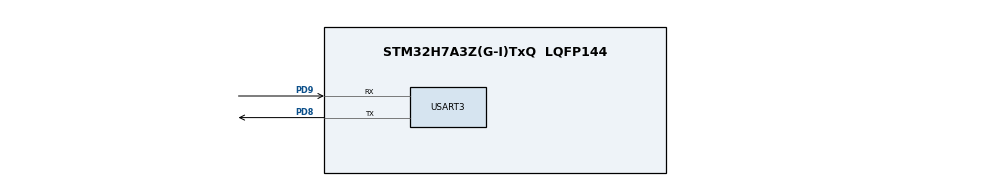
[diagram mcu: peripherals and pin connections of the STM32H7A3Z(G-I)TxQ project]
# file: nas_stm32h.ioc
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Mcu.Family=STM32H7
RCC.DFSDMCLockSelection=RCC_DFSDM1CLKSOURCE_D2PCLK1
PH0-OSC_IN.Signal=RCC_OSC_IN
RCC.CortexFreq_Value=100000000
STMicroelectronics.X-CUBE-AI.8.0.1.useInputAllocation=true
STMicroelectronics.X-CUBE-AI.8.0.1.ModelNameList=network
RCC.PLLFRACN=4096
STMicroelectronics.X-CUBE-AI.8.0.1.MaximumNumberOfInputLayer=1
STMicroelectronics.X-CUBE-AI.8.0.1.customLayerConfigEnabled=false
RCC.PLL2FRACN=0
STMicroelectronics.X-CUBE-AI.8.0.1.MaximumSizeOfOutputLayer=1
PD9.Mode=Asynchronous
RCC.SYSCLKSource=RCC_SYSCLKSOURCE_PLLCLK
ProjectManager.StackSize=0x800
RCC.SPI123CLockSelection=RCC_SPI123CLKSOURCE_PLL
USART3.VirtualMode-Asynchronous=VM_ASYNC
RCC.LPUART1CLockSelection=RCC_LPUART1CLKSOURCE_D3PCLK1
STMicroelectronics.X-CUBE-AI.8.0.1.copyWeightToRam=false
RCC.I2C4CLockSelection=RCC_I2C4CLKSOURCE_D3PCLK1
RCC.RCC_MCO2Source=RCC_MCO2SOURCE_SYSCLK
RCC.ADCCLockSelection=RCC_ADCCLKSOURCE_PLL2
RCC.HCLKFreq_Value=100000000
RCC.SAI2BCLockSelection=RCC_SAI2BCLKSOURCE_PLL
STMicroelectronics.X-CUBE-AI.8.0.1.XAaCUBEAaAICcArtificialOoIntelligenceJjCore=true
STMicroelectronics.X-CUBE-AI.8.0.1.ModelRamOccupation-0abbc9bb6c1aad92f61149516d385fa65a44edc42774e28c7ebe2bdf62b45bf3=78772
PD8.Signal=USART3_TX
STMicroelectronics.X-CUBE-AI.8.0.1.ModelActualCompression-0abbc9bb6c1aad92f61149516d385fa65a44edc42774e28c7ebe2bdf62b45bf3=0.0
PH0-OSC_IN.Mode=HSE-External-Clock-Source
RCC.HSE_VALUE=8000000
RCC.I2C123CLockSelection=RCC_I2C123CLKSOURCE_D2PCLK1
STMicroelectronics.X-CUBE-AI.8.0.1.ModelHashList=0abbc9bb6c1aad92f61149516d385fa65a44edc42774e28c7ebe2bdf62b45bf3
RCC.DIVM1=4
RCC.RCC_MCO1Source=RCC_MCO1SOURCE_HSI
STMicroelectronics.X-CUBE-AI.8.0.1.MaximumNumberOfOutputLayer=1
STMicroelectronics.X-CUBE-AI.8.0.1.ReadyForCodeGeneration=true
RCC.LPTIM2CLockSelection=RCC_LPTIM2CLKSOURCE_D3PCLK1
RCC.SAI1CLockSelection=RCC_SAI1CLKSOURCE_PLL
STMicroelectronics.X-CUBE-AI.8.0.1.ModelKind-0abbc9bb6c1aad92f61149516d385fa65a44edc42774e28c7ebe2bdf62b45bf3=TFLITE
RCC.LPTIM345CLockSelection=RCC_LPTIM3CLKSOURCE_D3PCLK1
RCC.SPDIFCLockSelection=RCC_SPDIFRXCLKSOURCE_PLL
RCC.CKPERSourceSelection=RCC_CLKPSOURCE_HSI
STMicroelectronics.X-CUBE-AI.8.0.1.ActivationSizes=AI_NETWORK_DATA_ACTIVATION_1_SIZE
RCC.APB3Freq_Value=50000000
Mcu.Package=LQFP144
STMicroelectronics.X-CUBE-AI.8.0.1.useOutputAllocation=true
RCC.PLL3FRACN=0
STMicroelectronics.X-CUBE-AI.8.0.1.LatestDirectoryUsed-0abbc9bb6c1aad92f61149516d385fa65a44edc42774e28c7ebe2bdf62b45bf3=F\:\\verified_model
STMicroelectronics.X-CUBE-AI.8.0.1.ActivationNames=pool0
STMicroelectronics.X-CUBE-AI.8.0.1.ModelFlashOccupation-0abbc9bb6c1aad92f61149516d385fa65a44edc42774e28c7ebe2bdf62b45bf3=397440
RCC.APB4Freq_Value=50000000
RCC.FDCANCLockSelection=RCC_FDCANCLKSOURCE_PLL
STMicroelectronics.X-CUBE-AI.8.0.1.ActivationBuffers=pool0
STMicroelectronics.X-CUBE-AI.8.0.1.ModelType-0abbc9bb6c1aad92f61149516d385fa65a44edc42774e28c7ebe2bdf62b45bf3=STM32Cube.AI runtime
RCC.SRDPPRE=RCC_APB4_DIV2
RCC.HSI48_VALUE=48000000
CORTEX_M7.CPU_ICache=Enabled
STMicroelectronics.X-CUBE-AI.8.0.1.HeapSize=0x800
RCC.EXTERNAL_CLOCK_VALUE=12288000
STMicroelectronics.X-CUBE-AI.8.0.1.ModelCompression-0abbc9bb6c1aad92f61149516d385fa65a44edc42774e28c7ebe2bdf62b45bf3=None
PD9.Signal=USART3_RX
RCC.Cortex_DivARG=SystemCoreClock/1000
RCC.CDPPRE1=RCC_APB1_DIV2
RCC.CDPPRE2=RCC_APB2_DIV2
ProjectManager.TargetToolchain=STM32CubeIDE
RCC.SPI6CLockSelection=RCC_SPI6CLKSOURCE_D3PCLK1
STMicroelectronics.X-CUBE-AI.8.0.1.StackSize=0x800
RCC.CECCLockSelection=RCC_CECCLKSOURCE_LSI
RCC.DIVN1=12
RCC.LPTIM1CLockSelection=RCC_LPTIM1CLKSOURCE_D2PCLK1
RCC.USBFreq_Value=100000000
RCC.SWPCLockSelection=RCC_SWPMI1CLKSOURCE_D2PCLK1
RCC.LSE_VALUE=32768
PD8.Mode=Asynchronous
RCC.USBCLockSelection=RCC_USBCLKSOURCE_PLL
STMicroelectronics.X-CUBE-AI.8.0.1.MaximumSizeOfInputLayer=1
board=custom
STMicroelectronics.X-CUBE-AI.8.0.1.ActivationBufferSizeList=78772
RCC.APB2Freq_Value=50000000
RCC.RNGCLockSelection=RCC_RNGCLKSOURCE_HSI48
RCC.FMCCLockSelection=RCC_FMCCLKSOURCE_D1HCLK
STMicroelectronics.X-CUBE-AI.8.0.1.ModelStructureFile-0abbc9bb6c1aad92f61149516d385fa65a44edc42774e28c7ebe2bdf62b45bf3=F\:\\verified_model\\nas_full_integer_quant.tflite
RCC.ADCFreq_Value=129000000
STMicroelectronics.X-CUBE-AI.8.0.1.ModelName-0abbc9bb6c1aad92f61149516d385fa65a44edc42774e28c7ebe2bdf62b45bf3=network
RCC.CSI_VALUE=4000000
RCC.CDPPRE=RCC_APB3_DIV2
Mcu.Name=STM32H7A3Z(G-I)TxQ
VP_STMicroelectronics.X-CUBE-AI_VS_ArtificialOoIntelligenceJjXAaCUBEAaAI_8.0.1.Mode=ArtificialOoIntelligenceJjXAaCUBEAaAI
STMicroelectronics.X-CUBE-AI.8.0.1.ModelMacc-0abbc9bb6c1aad92f61149516d385fa65a44edc42774e28c7ebe2bdf62b45bf3=36473034
RCC.SYSCLKFreq_VALUE=100000000
RCC.Spi45ClockSelection=RCC_SPI45CLKSOURCE_D2PCLK1
STMicroelectronics.X-CUBE-AI.8.0.1.WorkingBufferStartAddrList=0xFFFFFFFF
RCC.QSPICLockSelection=RCC_OSPICLKSOURCE_D1HCLK
ProjectManager.HeapSize=0x800
RCC.HSI_VALUE=64000000
NVIC.PriorityGroup=NVIC_PRIORITYGROUP_4
RCC.USART234578CLockSelection=RCC_USART234578CLKSOURCE_D2PCLK1
CORTEX_M7.CPU_DCache=Enabled
RCC.APB1Freq_Value=50000000
VP_CRC_VS_CRC.Mode=CRC_Activate
RCC.USART16CLockSelection=RCC_USART16910CLKSOURCE_D2PCLK2
STMicroelectronics.X-CUBE-AI.8.0.1.InternalRamActivationBufferMaxSize=AI_NETWORK_DATA_ACTIVATIONS_SIZE

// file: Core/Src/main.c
/* USER CODE BEGIN Header */
/**
  ******************************************************************************
  * @file           : main.c
  * @brief          : Main program body
  ******************************************************************************
  * @attention
  *
  * <h2><center>&copy; Copyright (c) 2025 STMicroelectronics.
  * All rights reserved.</center></h2>
  *
  * This software component is licensed by ST under BSD 3-Clause license,
  * the "License"; You may not use this file except in compliance with the
  * License. You may obtain a copy of the License at:
  *                        opensource.org/licenses/BSD-3-Clause
  *
  ******************************************************************************
  */
/* USER CODE END Header */
#include "main.h"

/* USER CODE BEGIN Includes */
/* USER CODE BEGIN Includes */
#include <stdio.h>
#include "network.h"
#include "network_data.h"
#include "ai_datatypes_defines.h"
#include "ai_platform.h"
#include <math.h>

/* USER CODE END Includes */

/* USER CODE END Includes */

CRC_HandleTypeDef hcrc;

UART_HandleTypeDef huart3;

void SystemClock_Config(void);
static void MX_GPIO_Init(void);
static void MX_CRC_Init(void);
static void MX_USART3_UART_Init(void);

/* USER CODE BEGIN 0 */
/* USER CODE BEGIN 0 */
/* Global handle to reference the instantiated C-model */
static ai_handle network = AI_HANDLE_NULL;

/* Global c-array to handle the activations buffer */
AI_ALIGNED(32)
static ai_u8 activations[AI_NETWORK_DATA_ACTIVATIONS_SIZE];

/* Array to store the data of the input tensor */
AI_ALIGNED(32)
static ai_float in_data[AI_NETWORK_IN_1_SIZE];
/* or static ai_u8 in_data[AI_NETWORK_IN_1_SIZE_BYTES]; */

/* c-array to store the data of the output tensor */
AI_ALIGNED(32)
static ai_float out_data[AI_NETWORK_OUT_1_SIZE];
/* static ai_u8 out_data[AI_NETWORK_OUT_1_SIZE_BYTES]; */

/* Array of pointer to manage the model's input/output tensors */
static ai_buffer *ai_input;
static ai_buffer *ai_output;

/* Define global variables */
char buf[50]; // Define printf
int buf_len = 0;
ai_error err;
//
int acquire_and_process_data(const void *in_data){

//	AI_ALIGNED(4) ai_i8 in_data[AI_SINE_MODEL_IN_1_SIZE_BYTES];
//	AI_ALIGNED(4) ai_i8 out_data[AI_SINE_MODEL_OUT_1_SIZE_BYTES];

	for (uint32_t i = 0; i < AI_NETWORK_IN_1_SIZE; i++)
	{
		((ai_float *)in_data)[i] = (ai_float)2.0f;
	}

	return 0;
}
int aiInit(void) {
//  ai_error err;

  /* Create and initialize the c-model */
  const ai_handle acts[] = { activations };
  err = ai_network_create_and_init(&network, acts, NULL);
  if (err.type != AI_ERROR_NONE) {
	  buf_len = sprintf(buf, "Error: could not create NN instance\r\n");
	  HAL_UART_Transmit(&huart3, (uint8_t *)buf, buf_len, 100);
	  while(1);
 };

  /* Reteive pointers to the model's input/output tensors */
  ai_input = ai_network_inputs_get(network, NULL);
  ai_output = ai_network_outputs_get(network, NULL);

  return 0;
}

int aiRun(const void *in_data, void *out_data) {
  ai_i32 n_batch;
//  ai_error err;

  /* 1 - Update IO handlers with the data payload */
  ai_input[0].data = AI_HANDLE_PTR(in_data);
  ai_output[0].data = AI_HANDLE_PTR(out_data);

  /* 2 - Perform the inference */
  n_batch = ai_network_run(network, &ai_input[0], &ai_output[0]);
  if (n_batch != 1) {
      err = ai_network_get_error(network);
	  buf_len = sprintf(buf, "Error: could not run inference \r\n");
	  HAL_UART_Transmit(&huart3, (uint8_t *)buf, buf_len, 100);

  };

  return 0;
}

int post_process(void *out_data){
	float y_val = ((float *)out_data)[0];
	buf_len = sprintf(buf,"Output: %f", y_val);
	HAL_UART_Transmit(&huart3, (uint8_t *)buf, buf_len, 100);

	return 0;
}

int softmax_process(void *out_data)
{
    float *logits = (float *)out_data;

    float max_val = logits[0];
    for (int i = 1; i < AI_NETWORK_OUT_1_SIZE; i++)
    {
        if (logits[i] > max_val)
        {
            max_val = logits[i];
        }
    }

    float sum_exp = 0.0f;
    for (int i = 0; i < AI_NETWORK_OUT_1_SIZE; i++)
    {
        logits[i] = expf(logits[i] - max_val);
        sum_exp += logits[i];
    }

    for (int i = 0; i < AI_NETWORK_OUT_1_SIZE; i++)
    {
        logits[i] /= sum_exp;
    }

//    buf_len = sprintf(buf, "Output[0] = %f\r\n", logits[0]);
//    HAL_UART_Transmit(&huart3, (uint8_t *)buf, buf_len, 100);

    return 0;
}

/* USER CODE END 0 */

/* USER CODE END 0 */

int main(void)
{
  /* USER CODE BEGIN 1 */
	/* USER CODE BEGIN 1 */

	__HAL_RCC_CRC_CLK_ENABLE();

	uint32_t timestamp;

	/* USER CODE END 1 */

  /* USER CODE END 1 */

  /* Enable I-Cache---------------------------------------------------------*/
  SCB_EnableICache();

  /* Enable D-Cache---------------------------------------------------------*/
  SCB_EnableDCache();

  /* MCU Configuration--------------------------------------------------------*/

  /* Reset of all peripherals, Initializes the Flash interface and the Systick. */
  HAL_Init();

  /* Configure the system clock */
  SystemClock_Config();

  /* Initialize all configured peripherals */
  MX_GPIO_Init();
  MX_CRC_Init();
  MX_USART3_UART_Init();
  /* USER CODE BEGIN 2 */
  /* USER CODE BEGIN 2 */

  HAL_UART_Init(&huart3);
  // Greetings
  buf_len = sprintf(buf, "\r\n\r\nSTM32 X-Cube-AI test\r\n");
  HAL_UART_Transmit(&huart3, (uint8_t *)buf, buf_len, 100);

  /* USER CODE END 2 */

  /* USER CODE END 2 */

  /* Infinite loop */
  while (1)
  {
	  /* 1 - Acquire, pre-process and fill the input buffers */
	  uint32_t start_time_init = HAL_GetTick(); // time start
	  for (int i = 0; i < 1000; i++)
	  {
		  aiInit();
		  acquire_and_process_data(in_data);
	  }
	  uint32_t end_time_init = HAL_GetTick(); // time end
	  uint32_t total_time_init = end_time_init - start_time_init;
	  float average_time_init = (float)total_time_init / 1000; // ms
	  char buf_init[32];
	  int buf_len_init = sprintf(buf_init, "Init Time: %.3f ms\r\n", average_time_init);
	  HAL_UART_Transmit(&huart3, (uint8_t *)buf_init, buf_len_init, HAL_MAX_DELAY);

	  /* 2 - Call inference engine */
	  uint32_t start_time_inf = HAL_GetTick(); // time start

	  for (int i = 0; i < 1; i++)
	  {
		  aiRun(in_data, out_data);
	  }

	  uint32_t end_time_inf = HAL_GetTick(); // time end
	  uint32_t total_time_inf = end_time_inf - start_time_inf;
	  float average_time_inf = (float)total_time_inf / 1; // ms
	  char buf_inf[32];
	  int buf_len_inf = sprintf(buf_inf, "CNN Time: %.3f ms\r\n", average_time_inf);
	  HAL_UART_Transmit(&huart3, (uint8_t *)buf_inf, buf_len_inf, HAL_MAX_DELAY);

	  /* 3 - Post-process the predictions */
//	  post_process(out_data);
	  uint32_t start_time_sm = HAL_GetTick(); // time start
	  for (int i = 0; i < 1000; i++)
	  {
	      softmax_process(out_data);
	  }
	  uint32_t end_time_sm = HAL_GetTick(); // time end
	  uint32_t total_time_sm = end_time_sm - start_time_sm;
	  float average_time_sm = (float)total_time_sm / 1000; // ms
	  char buf_sm[32];
	  int buf_len_sm = sprintf(buf_sm, "Softmax Time: %.3f ms\r\n", average_time_sm);
	  HAL_UART_Transmit(&huart3, (uint8_t *)buf_sm, buf_len_sm, HAL_MAX_DELAY);

	  /* USER CODE END WHILE */
	  HAL_Delay(500);

  }
}

void SystemClock_Config(void)
{
  RCC_OscInitTypeDef RCC_OscInitStruct = {0};
  RCC_ClkInitTypeDef RCC_ClkInitStruct = {0};

  /** Supply configuration update enable
  */
  HAL_PWREx_ConfigSupply(PWR_DIRECT_SMPS_SUPPLY);
  /** Configure the main internal regulator output voltage
  */
  __HAL_PWR_VOLTAGESCALING_CONFIG(PWR_REGULATOR_VOLTAGE_SCALE2);

  while(!__HAL_PWR_GET_FLAG(PWR_FLAG_VOSRDY)) {}
  /** Initializes the RCC Oscillators according to the specified parameters
  * in the RCC_OscInitTypeDef structure.
  */
  RCC_OscInitStruct.OscillatorType = RCC_OSCILLATORTYPE_HSI;
  RCC_OscInitStruct.HSIState = RCC_HSI_DIV1;
  RCC_OscInitStruct.HSICalibrationValue = RCC_HSICALIBRATION_DEFAULT;
  RCC_OscInitStruct.PLL.PLLState = RCC_PLL_ON;
  RCC_OscInitStruct.PLL.PLLSource = RCC_PLLSOURCE_HSI;
  RCC_OscInitStruct.PLL.PLLM = 4;
  RCC_OscInitStruct.PLL.PLLN = 12;
  RCC_OscInitStruct.PLL.PLLP = 2;
  RCC_OscInitStruct.PLL.PLLQ = 2;
  RCC_OscInitStruct.PLL.PLLR = 2;
  RCC_OscInitStruct.PLL.PLLRGE = RCC_PLL1VCIRANGE_3;
  RCC_OscInitStruct.PLL.PLLVCOSEL = RCC_PLL1VCOWIDE;
  RCC_OscInitStruct.PLL.PLLFRACN = 4096;
  if (HAL_RCC_OscConfig(&RCC_OscInitStruct) != HAL_OK)
  {
    Error_Handler();
  }
  /** Initializes the CPU, AHB and APB buses clocks
  */
  RCC_ClkInitStruct.ClockType = RCC_CLOCKTYPE_HCLK|RCC_CLOCKTYPE_SYSCLK
                              |RCC_CLOCKTYPE_PCLK1|RCC_CLOCKTYPE_PCLK2
                              |RCC_CLOCKTYPE_D3PCLK1|RCC_CLOCKTYPE_D1PCLK1;
  RCC_ClkInitStruct.SYSCLKSource = RCC_SYSCLKSOURCE_PLLCLK;
  RCC_ClkInitStruct.SYSCLKDivider = RCC_SYSCLK_DIV1;
  RCC_ClkInitStruct.AHBCLKDivider = RCC_HCLK_DIV1;
  RCC_ClkInitStruct.APB3CLKDivider = RCC_APB3_DIV2;
  RCC_ClkInitStruct.APB1CLKDivider = RCC_APB1_DIV2;
  RCC_ClkInitStruct.APB2CLKDivider = RCC_APB2_DIV2;
  RCC_ClkInitStruct.APB4CLKDivider = RCC_APB4_DIV2;

  if (HAL_RCC_ClockConfig(&RCC_ClkInitStruct, FLASH_LATENCY_2) != HAL_OK)
  {
    Error_Handler();
  }
}

static void MX_CRC_Init(void)
{

  hcrc.Instance = CRC;
  hcrc.Init.DefaultPolynomialUse = DEFAULT_POLYNOMIAL_ENABLE;
  hcrc.Init.DefaultInitValueUse = DEFAULT_INIT_VALUE_ENABLE;
  hcrc.Init.InputDataInversionMode = CRC_INPUTDATA_INVERSION_NONE;
  hcrc.Init.OutputDataInversionMode = CRC_OUTPUTDATA_INVERSION_DISABLE;
  hcrc.InputDataFormat = CRC_INPUTDATA_FORMAT_BYTES;
  if (HAL_CRC_Init(&hcrc) != HAL_OK)
  {
    Error_Handler();
  }

}

static void MX_USART3_UART_Init(void)
{

  huart3.Instance = USART3;
  huart3.Init.BaudRate = 115200;
  huart3.Init.WordLength = UART_WORDLENGTH_8B;
  huart3.Init.StopBits = UART_STOPBITS_1;
  huart3.Init.Parity = UART_PARITY_NONE;
  huart3.Init.Mode = UART_MODE_TX_RX;
  huart3.Init.HwFlowCtl = UART_HWCONTROL_NONE;
  huart3.Init.OverSampling = UART_OVERSAMPLING_16;
  huart3.Init.OneBitSampling = UART_ONE_BIT_SAMPLE_DISABLE;
  huart3.Init.ClockPrescaler = UART_PRESCALER_DIV1;
  huart3.AdvancedInit.AdvFeatureInit = UART_ADVFEATURE_NO_INIT;
  if (HAL_UART_Init(&huart3) != HAL_OK)
  {
    Error_Handler();
  }
  if (HAL_UARTEx_SetTxFifoThreshold(&huart3, UART_TXFIFO_THRESHOLD_1_8) != HAL_OK)
  {
    Error_Handler();
  }
  if (HAL_UARTEx_SetRxFifoThreshold(&huart3, UART_RXFIFO_THRESHOLD_1_8) != HAL_OK)
  {
    Error_Handler();
  }
  if (HAL_UARTEx_DisableFifoMode(&huart3) != HAL_OK)
  {
    Error_Handler();
  }

}

static void MX_GPIO_Init(void)
{

  /* GPIO Ports Clock Enable */
  __HAL_RCC_GPIOH_CLK_ENABLE();
  __HAL_RCC_GPIOD_CLK_ENABLE();

}

void Error_Handler(void)
{
  __disable_irq();
  while (1)
  {
  }
}

/************************ (C) COPYRIGHT STMicroelectronics *****END OF FILE****/
